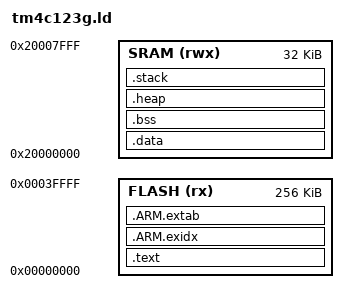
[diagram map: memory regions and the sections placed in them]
/******************************************************************************
 *
 * blinky.ld - Linker configuration file for blinky.
 *
 * Copyright (c) 2011-2017 Texas Instruments Incorporated.  All rights reserved.
 * Software License Agreement
 * 
 * Texas Instruments (TI) is supplying this software for use solely and
 * exclusively on TI's microcontroller products. The software is owned by
 * TI and/or its suppliers, and is protected under applicable copyright
 * laws. You may not combine this software with "viral" open-source
 * software in order to form a larger program.
 * 
 * THIS SOFTWARE IS PROVIDED "AS IS" AND WITH ALL FAULTS.
 * NO WARRANTIES, WHETHER EXPRESS, IMPLIED OR STATUTORY, INCLUDING, BUT
 * NOT LIMITED TO, IMPLIED WARRANTIES OF MERCHANTABILITY AND FITNESS FOR
 * A PARTICULAR PURPOSE APPLY TO THIS SOFTWARE. TI SHALL NOT, UNDER ANY
 * CIRCUMSTANCES, BE LIABLE FOR SPECIAL, INCIDENTAL, OR CONSEQUENTIAL
 * DAMAGES, FOR ANY REASON WHATSOEVER.
 * 
 * This is part of revision 2.1.4.178 of the DK-TM4C123G Firmware Package.
 *
 *****************************************************************************/

MEMORY
{
    /* 256KB Flash */
    FLASH (rx) : ORIGIN = 0x00000000, LENGTH = 0x00040000
    /* 32KB SRAM */
    SRAM (rwx) : ORIGIN = 0x20000000, LENGTH = 0x00008000
}

REGION_ALIAS("REGION_TEXT", FLASH);
REGION_ALIAS("REGION_ARM_EXIDX", FLASH);
REGION_ALIAS("REGION_ARM_EXTAB", FLASH);

REGION_ALIAS("REGION_BSS", SRAM);
REGION_ALIAS("REGION_DATA", SRAM);
REGION_ALIAS("REGION_STACK", SRAM);
REGION_ALIAS("REGION_HEAP", SRAM);

/* 8KB Heap */
HEAPSIZE = 0x2000;
/* 2KB Stack */
STACKSIZE = 0x800;

ENTRY(ResetISR)

SECTIONS
{
    .text :
    {
        _text = .;
        KEEP(*(.isr_vector))
        *(.text*)
        *(.rodata*)
        _etext = .;
    } > REGION_TEXT

    .ARM.exidx : {
        __exidx_start = .;
        *(.ARM.exidx* .gnu.linkonce.armexidx.*)
        __exidx_end = .;
    } > REGION_ARM_EXIDX

    .ARM.extab : {
        *(.ARM.extab* .gnu.linkonce.armextab.*)
    } > REGION_ARM_EXTAB

    .data : AT(ADDR(.text) + SIZEOF(.text))
    {
        _data = .;
        _ldata = LOADADDR (.data);
        *(vtable)
        *(.data*)
        _edata = .;
    } > REGION_DATA

    .bss :
    {
        _bss = .;
        *(.bss*)
        *(COMMON)
        _ebss = .;
    } > REGION_BSS

    .heap : {
        __heap_start__ = .;
        end = __heap_start__;
        _end = end;
        __end = end;
        . = . + HEAPSIZE;
        KEEP(*(.heap))
        __heap_end__ = .;
        __HeapLimit = __heap_end__;
    } > REGION_HEAP

    .stack : ALIGN(0x8) {
        _stack = .;
        __stack = .;
        . = . + STACKSIZE;
        __StackTop = . ;
        KEEP(*(.stack))
    } > REGION_STACK
}
